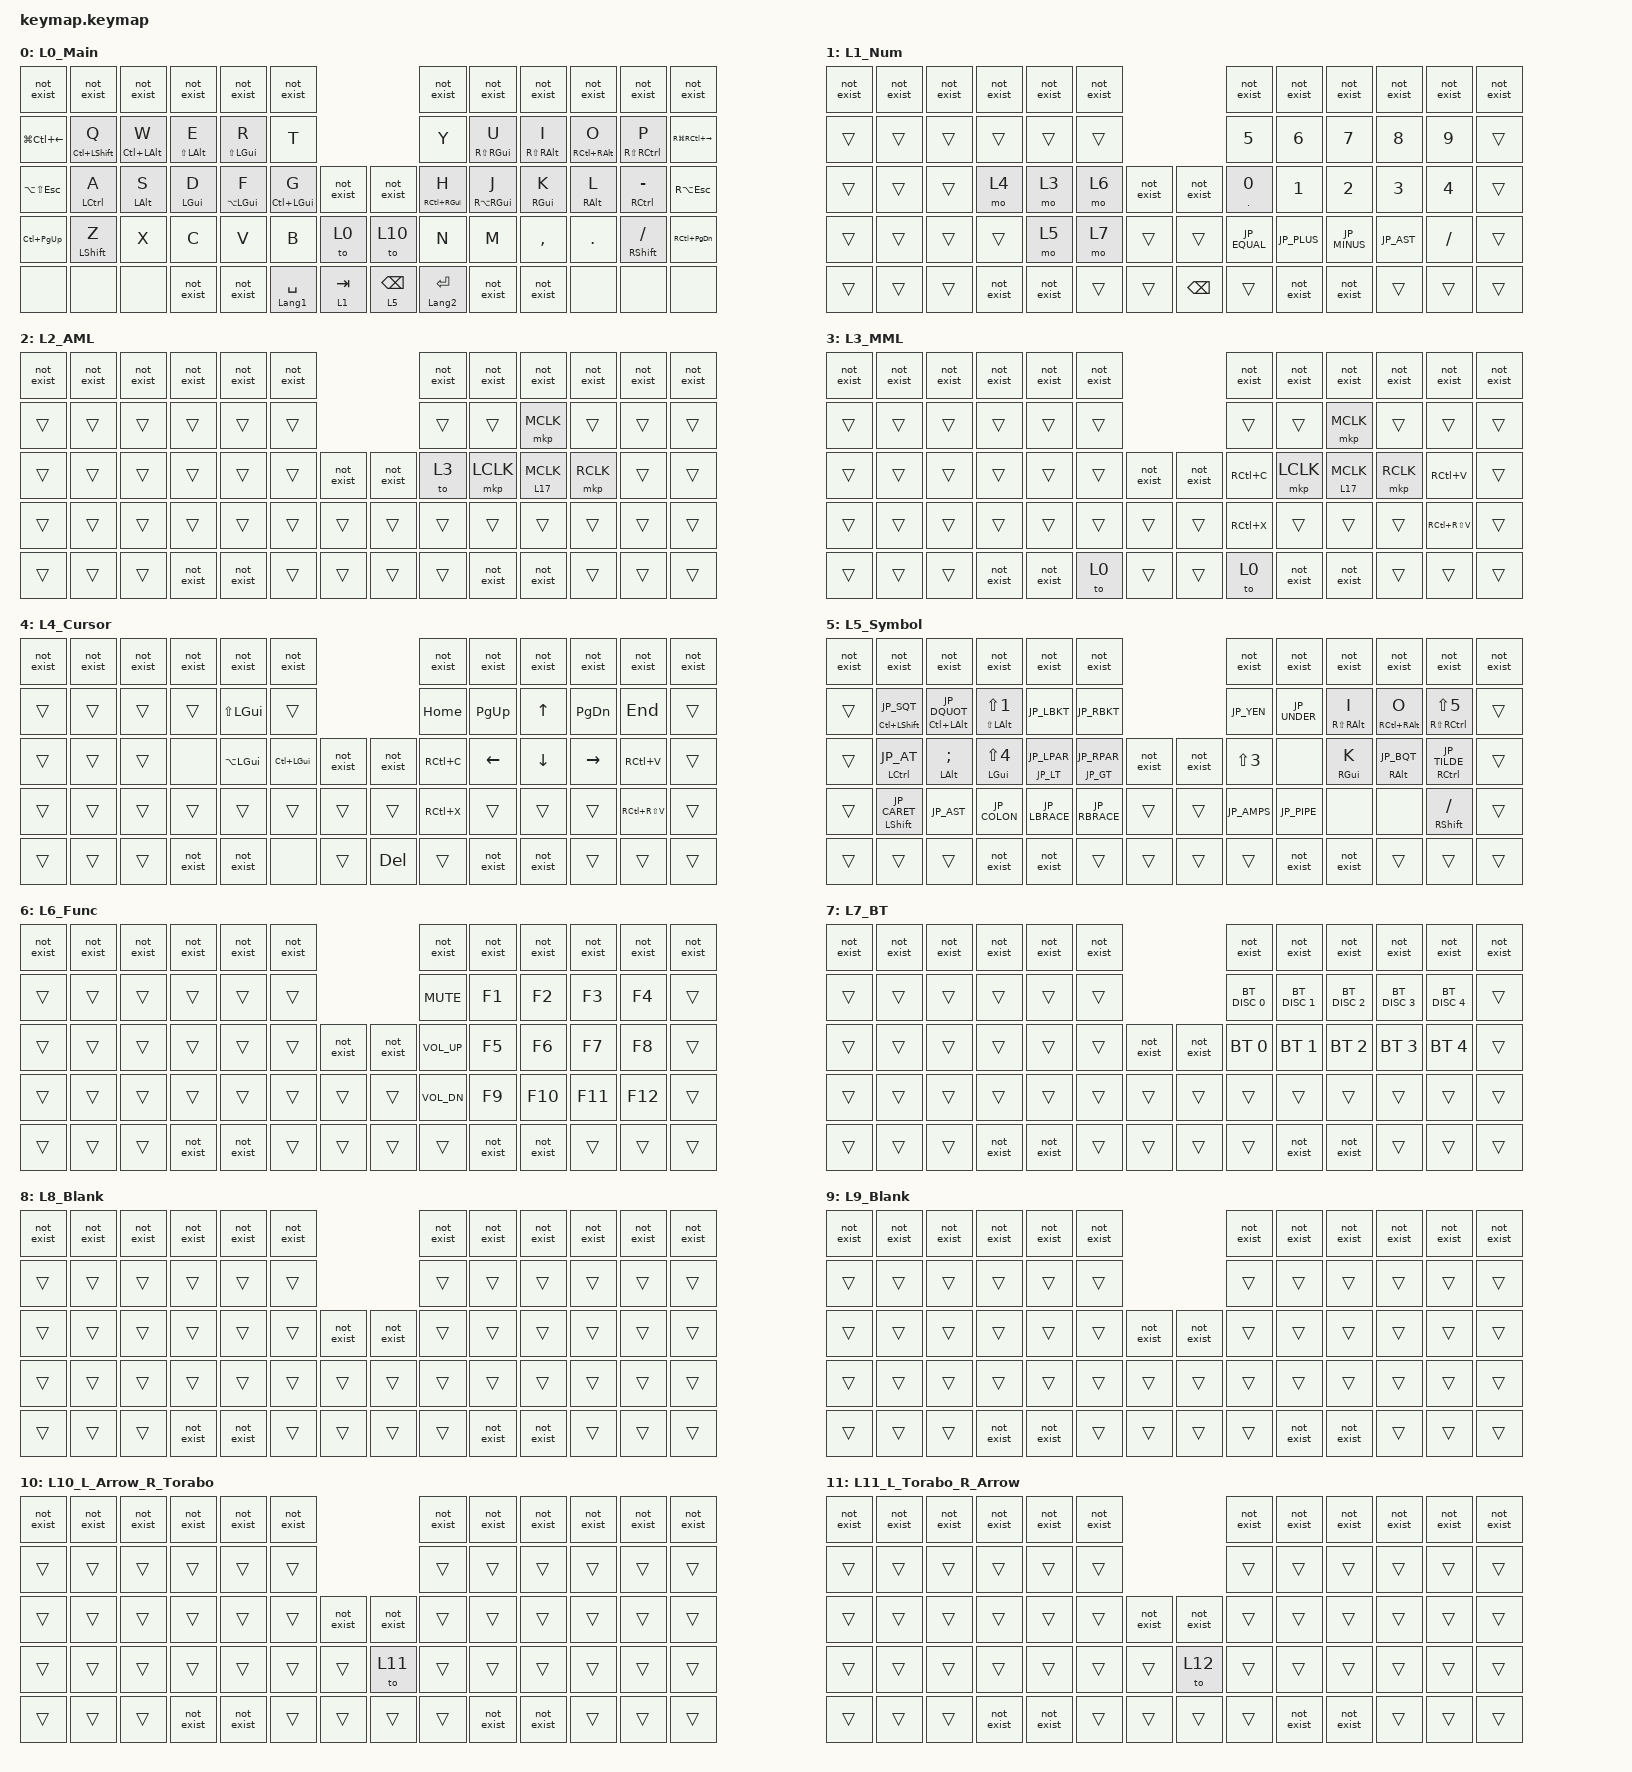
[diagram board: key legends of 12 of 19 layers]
/*
 * ZMK Keymap Configuration
 * 
 * Keyboard: torabo-tsuki lp(M) dual-torabo構成
 * Author: やきそば
 * 
 * 特徴:
 * - 基本はQWERTY配列、A-Ctrl、Z-Shift、S-Alt、D-Winなど
 * - 右小指(Lの右隣)は文章入力でよく使う長音記号（ー）を配置
 * - 左親指で数字レイヤー、+ホームポジション周辺キーで他レイヤーへのハブとしている
 * - 10～12レイヤーで左右トラボの挙動をトグル切り替え
 * - 17～18をスクロールレイヤー（慣性スクロール）
 */

#include <input/processors.dtsi>
#include <zephyr/dt-bindings/input/input-event-codes.h>
#include "keys_ja.h"
#include <dt-bindings/zmk/modifiers.h>
#include <behaviors.dtsi>
#include <dt-bindings/zmk/bt.h>
#include <dt-bindings/zmk/keys.h>
#include <dt-bindings/zmk/pointing.h>

/* --------------------------------------------------------------------------
 * 全般設定 (Global Settings)
 * -------------------------------------------------------------------------- */
// オーバーライド

&mt {
    tapping-term-ms = <150>; // 長押しの判定時間
    quick-tap-ms = <250>;    // 素早く2回叩いた時に連続入力として扱う設定
};

&lt {
    tapping-term-ms = <150>; // 長押しの判定時間
    quick-tap-ms = <250>;    // 素早く2回叩いた時に連続入力として扱う設定
};

/ {
    /* --------------------------------------------------------------------------
     * コンボ設定 (Combos)
     * 特定のキーを同時押しした際のアクション
     * -------------------------------------------------------------------------- */

    combos {
        compatible = "zmk,combos";

        // 13, 14キー(qw)同時押しで ESC

        Esc {
            bindings = <&kp ESC>;
            key-positions = <13 14>;
            slow-release;
        };

        // レイヤー7(BT)にて 47, 48, 49, 50キー(jkl-)同時押しで Bluetooth情報初期化

        BTclr {
            bindings = <&bt BT_CLR>;
            key-positions = <47 48 49 50>;
            slow-release;
            layers = <7>;
            timeout-ms = <0>;
        };

        // 35, 34キー(kl)で横スクロールレイヤー(18)へ

        x_scroll {
            bindings = <&mo 18>;
            key-positions = <35 34>;
            require-prior-idle-ms = <50>;
        };

        // 58, 59きーで BackSpace（連続入力用。でもダブルタップでできるので必要ないかも）

        CapsLock {
            bindings = <&kp LS(CLCK)>;
            key-positions = <39 50>;
        };

        ExitMML {
            bindings = <&to 0>;
            key-positions = <33 34 35>;
            layers = <3>;
        };
    };

    /* --------------------------------------------------------------------------
     * マクロ設定 (Macros)
     * -------------------------------------------------------------------------- */

    macros {
        // レイヤー2 (AML: Auto Mouse Layer) を強制OFFにする

        exit_AML: exit_AML {
            compatible = "zmk,behavior-macro";
            wait-ms = <0>;
            tap-ms = <0>;
            #binding-cells = <0>;
            bindings = <&tog_off 2>;
            label = "exit_AML";
        };

        // パラメータ付きマクロ: キーを入力した後に exit_AML を実行する

        kp_exit_AML: kp_exit_AML {
            compatible = "zmk,behavior-macro-one-param";
            wait-ms = <0>;
            tap-ms = <0>;
            #binding-cells = <1>;
            bindings = <&macro_param_1to1 &kp MACRO_PLACEHOLDER &exit_AML>;
            label = "KP_exit_AML";
        };

        // zip_temp_layer の状態を強制的に折り取るマクロ

        exit_mouse_layer: exit_mouse_layer {
            compatible = "zmk,behavior-macro";
            #binding-cells = <0>;
            wait-ms = <0>;
            tap-ms = <0>;
            bindings = <&tog 2>;
        };
    };

    /* --------------------------------------------------------------------------
     * カスタム挙動 (Behaviors)
     * -------------------------------------------------------------------------- */

    behaviors {
        // 物理的に存在しないキー用の透過設定

        not_exist: not_exist {
            compatible = "zmk,behavior-transparent";
            #binding-cells = <0>;
        };

        // Home Row Mods: 長押しで修飾キー、タップで通常文字

        hm: homerow_mods {
            compatible = "zmk,behavior-hold-tap";
            #binding-cells = <2>;
            tapping-term-ms = <300>;    // ① 時間：200msくらいが標準
            quick-tap-ms = <175>;       // ② 連打時の判定（任意）
            flavor = "tap-preferred";   // ★③ ここが最重要！
            bindings = <&kp>, <&kp>;
        };

        // Home Row Mods (高速入力用・短めの判定)

        hm_s: hm_s {
            compatible = "zmk,behavior-hold-tap";
            #binding-cells = <2>;
            tapping-term-ms = <180>;
            quick-tap-ms = <150>;
            flavor = "tap-preferred";
            bindings = <&kp>, <&kp>;
        };

        // 特定レイヤーをOFFにするトグル挙動

        tog_off: toggle_layer_off {
            compatible = "zmk,behavior-toggle-layer";
            #binding-cells = <1>;
            display-name = "Toggle Layer Off";
            toggle-mode = "off";
        };

        // タップ時にAML(マウス層)を解除しつつキー入力する特殊なHold-Tap

        mt_exit_AML_on_tap: mt_exit_AML_on_tap {
            compatible = "zmk,behavior-hold-tap";
            bindings = <&kp>, <&kp_exit_AML>;

            #binding-cells = <2>;
            tapping-term-ms = <299>;
            quick-tap-ms = <175>;       // ② 連打時の判定（任意）
            flavor = "tap-preferred";   // ★③ ここが最重要！
        };

        // マウスボタン用レイヤーホールド (長押しでレイヤー、タップでクリック)

        ml: ml {
            compatible = "zmk,behavior-hold-tap";
            bindings = <&mo>, <&mkp>;

            #binding-cells = <2>;
            tapping-term-ms = <200>;
        };

        // オートマウス脱出用の「超即時Hold」Behavior
    };

    /* --------------------------------------------------------------------------
     * キーマップ (Keymaps)
     * -------------------------------------------------------------------------- */

    keymap {
        compatible = "zmk,keymap";

        // [0] メインレイヤー: QWERTY配列
        // A-Ctrl、Z-Shift、S‐Alt、D-Win（右手も対称に配置）
        // 親指にはスペース(レイヤー)、タブ(日本語)、BackSpace(英数)、エンター(レイヤー)

        L0_Main {
            bindings = <
&not_exist              &not_exist                        &not_exist          &not_exist          &not_exist          &not_exist                                    &not_exist            &not_exist           &not_exist           &not_exist           &not_exist                            &not_exist
&kp LG(LC(LEFT_ARROW))  &hm LC(LEFT_SHIFT) Q              &hm LC(LEFT_ALT) W  &hm LS(LEFT_ALT) E  &hm LS(LEFT_GUI) R  &kp T                                         &kp Y                 &hm RS(RIGHT_GUI) U  &hm RS(RIGHT_ALT) I  &hm RC(RIGHT_ALT) O  &hm RS(RIGHT_CONTROL) P               &kp RG(RC(RIGHT_ARROW))
&kp LA(LS(ESC))         &mt_exit_AML_on_tap LCTRL A       &hm LEFT_ALT S      &hm LEFT_GUI D      &hm LA(LEFT_GUI) F  &hm LC(LEFT_GUI) G    &not_exist  &not_exist  &hm RC(RIGHT_GUI) H   &hm RA(RIGHT_GUI) J  &hm RIGHT_GUI K      &hm RIGHT_ALT L      &mt_exit_AML_on_tap RCTRL MINUS       &kp RA(ESC)
&kp LC(PAGE_UP)         &mt_exit_AML_on_tap LEFT_SHIFT Z  &kp X               &kp C               &kp V               &kp B                 &to 0       &to 10      &kp N                 &kp M                &kp COMMA            &kp DOT              &mt_exit_AML_on_tap RIGHT_SHIFT FSLH  &kp RC(PAGE_DOWN)
&none                   &none                             &none               &not_exist          &not_exist          &mt LANGUAGE_1 SPACE  &lt 1 TAB   &lt 5 BSPC  &mt LANGUAGE_2 ENTER  &not_exist           &not_exist           &none                &none                                 &none
            >;
        };

        // [1] 数字レイヤー (右手に0-9を二段配置)
        // 左手は親指+ホームポジション周辺の組み合わせで他レイヤーへのハブとしている。

        L1_Num {
            bindings = <
&not_exist  &not_exist  &not_exist  &not_exist  &not_exist  &not_exist                          &not_exist       &not_exist   &not_exist    &not_exist  &not_exist  &not_exist
&trans      &trans      &trans      &trans      &trans      &trans                              &kp N5           &kp N6       &kp N7        &kp N8      &kp N9      &trans
&trans      &trans      &trans      &mo 4       &mo 3       &mo 6       &not_exist  &not_exist  &hm_s PERIOD N0  &kp N1       &kp N2        &kp N3      &kp N4      &trans
&trans      &trans      &trans      &trans      &mo 5       &mo 7       &trans      &trans      &kp JP_EQUAL     &kp JP_PLUS  &kp JP_MINUS  &kp JP_AST  &kp SLASH   &trans
&trans      &trans      &trans      &not_exist  &not_exist  &trans      &trans      &kp BSPC    &trans           &not_exist   &not_exist    &trans      &trans      &trans
            >;
        };

        // [2] AML (Auto Mouse Layer): マウス操作用

        L2_AML {
            bindings = <
&not_exist  &not_exist  &not_exist  &not_exist  &not_exist  &not_exist                          &not_exist  &not_exist  &not_exist   &not_exist  &not_exist  &not_exist
&trans      &trans      &trans      &trans      &trans      &trans                              &trans      &trans      &mkp MCLK    &trans      &trans      &trans
&trans      &trans      &trans      &trans      &trans      &trans      &not_exist  &not_exist  &to 3       &mkp LCLK   &ml 17 MCLK  &mkp RCLK   &trans      &trans
&trans      &trans      &trans      &trans      &trans      &trans      &trans      &trans      &trans      &trans      &trans       &trans      &trans      &trans
&trans      &trans      &trans      &not_exist  &not_exist  &trans      &trans      &trans      &trans      &not_exist  &not_exist   &trans      &trans      &trans
            >;
        };

        // [3] MML (Mouse & Macro Layer): コピー、ペースト等

        L3_MML {
            bindings = <
&not_exist  &not_exist  &not_exist  &not_exist  &not_exist  &not_exist                          &not_exist  &not_exist  &not_exist   &not_exist  &not_exist     &not_exist
&trans      &trans      &trans      &trans      &trans      &trans                              &trans      &trans      &mkp MCLK    &trans      &trans         &trans
&trans      &trans      &trans      &trans      &trans      &trans      &not_exist  &not_exist  &kp RC(C)   &mkp LCLK   &ml 17 MCLK  &mkp RCLK   &kp RC(V)      &trans
&trans      &trans      &trans      &trans      &trans      &trans      &trans      &trans      &kp RC(X)   &trans      &trans       &trans      &kp RC(RS(V))  &trans
&trans      &trans      &trans      &not_exist  &not_exist  &to 0       &trans      &trans      &to 0       &not_exist  &not_exist   &trans      &trans         &trans
            >;
        };

        // [4] カーソルレイヤー: 矢印キー、Home/End等

        L4_Cursor {
            bindings = <
&not_exist  &not_exist  &not_exist  &not_exist  &not_exist        &not_exist                                &not_exist  &not_exist      &not_exist      &not_exist       &not_exist     &not_exist
&trans      &trans      &trans      &trans      &kp LS(LEFT_GUI)  &trans                                    &kp HOME    &kp PAGE_UP     &kp UP_ARROW    &kp PAGE_DOWN    &kp END        &trans
&trans      &trans      &trans      &none       &kp LA(LEFT_GUI)  &kp LC(LEFT_GUI)  &not_exist  &not_exist  &kp RC(C)   &kp LEFT_ARROW  &kp DOWN_ARROW  &kp RIGHT_ARROW  &kp RC(V)      &trans
&trans      &trans      &trans      &trans      &trans            &trans            &trans      &trans      &kp RC(X)   &trans          &trans          &trans           &kp RC(RS(V))  &trans
&trans      &trans      &trans      &not_exist  &not_exist        &none             &trans      &kp DEL     &trans      &not_exist      &not_exist      &trans           &trans         &trans
            >;
        };

        // [5] 記号レイヤー: 下記の記事を参考に、連想しやすい記号配列を設定
        // https://qiita.com/rall_alice/items/1c5cafc15dc8a7ad6236

        L5_Symbol {
            bindings = <
&not_exist  &not_exist                               &not_exist                 &not_exist                     &not_exist           &not_exist                                   &not_exist        &not_exist    &not_exist           &not_exist            &not_exist                             &not_exist
&trans      &hm LC(LEFT_SHIFT) JP_SQT                &hm LC(LEFT_ALT) JP_DQUOT  &hm LS(LEFT_ALT) LS(NUMBER_1)  &kp JP_LBKT          &kp JP_RBKT                                  &kp JP_YEN        &kp JP_UNDER  &hm RS(RIGHT_ALT) I  &hm RC(RIGHT_ALT) O   &hm RS(RIGHT_CONTROL) LS(NUMBER_5)     &trans
&trans      &mt_exit_AML_on_tap LCTRL JP_AT          &hm LEFT_ALT SEMICOLON     &hm LEFT_GUI LS(NUMBER_4)      &hm_s JP_LT JP_LPAR  &hm_s JP_GT JP_RPAR  &not_exist  &not_exist  &kp LS(NUMBER_3)  &none         &hm RIGHT_GUI K      &hm RIGHT_ALT JP_BQT  &mt_exit_AML_on_tap RCTRL JP_TILDE     &trans
&trans      &mt_exit_AML_on_tap LEFT_SHIFT JP_CARET  &kp JP_AST                 &kp JP_COLON                   &kp JP_LBRACE        &kp JP_RBRACE        &trans      &trans      &kp JP_AMPS       &kp JP_PIPE   &none                &none                 &mt_exit_AML_on_tap RIGHT_SHIFT SLASH  &trans
&trans      &trans                                   &trans                     &not_exist                     &not_exist           &trans               &trans      &trans      &trans            &not_exist    &not_exist           &trans                &trans                                 &trans
            >;
        };

        // [6] ファンクションレイヤー: F1-F12（おまけで音量調節）

        L6_Func {
            bindings = <
&not_exist  &not_exist  &not_exist  &not_exist  &not_exist  &not_exist                          &not_exist    &not_exist  &not_exist  &not_exist  &not_exist  &not_exist
&trans      &trans      &trans      &trans      &trans      &trans                              &kp C_MUTE    &kp F1      &kp F2      &kp F3      &kp F4      &trans
&trans      &trans      &trans      &trans      &trans      &trans      &not_exist  &not_exist  &kp C_VOL_UP  &kp F5      &kp F6      &kp F7      &kp F8      &trans
&trans      &trans      &trans      &trans      &trans      &trans      &trans      &trans      &kp C_VOL_DN  &kp F9      &kp F10     &kp F11     &kp F12     &trans
&trans      &trans      &trans      &not_exist  &not_exist  &trans      &trans      &trans      &trans        &not_exist  &not_exist  &trans      &trans      &trans
            >;
        };

        // [7] Bluetoothレイヤー: 接続先の切り替え・解除

        L7_BT {
            bindings = <
&not_exist  &not_exist  &not_exist  &not_exist  &not_exist  &not_exist                          &not_exist     &not_exist     &not_exist     &not_exist     &not_exist     &not_exist
&trans      &trans      &trans      &trans      &trans      &trans                              &bt BT_DISC 0  &bt BT_DISC 1  &bt BT_DISC 2  &bt BT_DISC 3  &bt BT_DISC 4  &trans
&trans      &trans      &trans      &trans      &trans      &trans      &not_exist  &not_exist  &bt BT_SEL 0   &bt BT_SEL 1   &bt BT_SEL 2   &bt BT_SEL 3   &bt BT_SEL 4   &trans
&trans      &trans      &trans      &trans      &trans      &trans      &trans      &trans      &trans         &trans         &trans         &trans         &trans         &trans
&trans      &trans      &trans      &not_exist  &not_exist  &trans      &trans      &trans      &trans         &not_exist     &not_exist     &trans         &trans         &trans
            >;
        };

        // [8] 空レイヤー (予約)

        L8_Blank {
            bindings = <
&not_exist  &not_exist  &not_exist  &not_exist  &not_exist  &not_exist                          &not_exist  &not_exist  &not_exist  &not_exist  &not_exist  &not_exist
&trans      &trans      &trans      &trans      &trans      &trans                              &trans      &trans      &trans      &trans      &trans      &trans
&trans      &trans      &trans      &trans      &trans      &trans      &not_exist  &not_exist  &trans      &trans      &trans      &trans      &trans      &trans
&trans      &trans      &trans      &trans      &trans      &trans      &trans      &trans      &trans      &trans      &trans      &trans      &trans      &trans
&trans      &trans      &trans      &not_exist  &not_exist  &trans      &trans      &trans      &trans      &not_exist  &not_exist  &trans      &trans      &trans
            >;
        };

        // [9] 空レイヤー (予約)

        L9_Blank {
            bindings = <
&not_exist  &not_exist  &not_exist  &not_exist  &not_exist  &not_exist                          &not_exist  &not_exist  &not_exist  &not_exist  &not_exist  &not_exist
&trans      &trans      &trans      &trans      &trans      &trans                              &trans      &trans      &trans      &trans      &trans      &trans
&trans      &trans      &trans      &trans      &trans      &trans      &not_exist  &not_exist  &trans      &trans      &trans      &trans      &trans      &trans
&trans      &trans      &trans      &trans      &trans      &trans      &trans      &trans      &trans      &trans      &trans      &trans      &trans      &trans
&trans      &trans      &trans      &not_exist  &not_exist  &trans      &trans      &trans      &trans      &not_exist  &not_exist  &trans      &trans      &trans
            >;
        };

        // [10] 左右トラボ挙動レイヤーをトグル切り替え（0→10→11→12→0）
        // 左トラボ：矢印キー入力、右トラボ：通常

        L10_L_Arrow_R_Torabo {
            bindings = <
&not_exist  &not_exist  &not_exist  &not_exist  &not_exist  &not_exist                          &not_exist  &not_exist  &not_exist  &not_exist  &not_exist  &not_exist
&trans      &trans      &trans      &trans      &trans      &trans                              &trans      &trans      &trans      &trans      &trans      &trans
&trans      &trans      &trans      &trans      &trans      &trans      &not_exist  &not_exist  &trans      &trans      &trans      &trans      &trans      &trans
&trans      &trans      &trans      &trans      &trans      &trans      &trans      &to 11      &trans      &trans      &trans      &trans      &trans      &trans
&trans      &trans      &trans      &not_exist  &not_exist  &trans      &trans      &trans      &trans      &not_exist  &not_exist  &trans      &trans      &trans
            >;
        };

        // [11] 左右トラボ挙動レイヤーをトグル切り替え（0→10→11→12→0）
        // 左トラボ：通常、右トラボ：矢印入力

        L11_L_Torabo_R_Arrow {
            bindings = <
&not_exist  &not_exist  &not_exist  &not_exist  &not_exist  &not_exist                          &not_exist  &not_exist  &not_exist  &not_exist  &not_exist  &not_exist
&trans      &trans      &trans      &trans      &trans      &trans                              &trans      &trans      &trans      &trans      &trans      &trans
&trans      &trans      &trans      &trans      &trans      &trans      &not_exist  &not_exist  &trans      &trans      &trans      &trans      &trans      &trans
&trans      &trans      &trans      &trans      &trans      &trans      &trans      &to 12      &trans      &trans      &trans      &trans      &trans      &trans
&trans      &trans      &trans      &not_exist  &not_exist  &trans      &trans      &trans      &trans      &not_exist  &not_exist  &trans      &trans      &trans
            >;
        };

        // [11] 左右トラボ挙動レイヤーをトグル切り替え（0→10→11→12→0）
        // 左トラボ：通常、右トラボ：矢印入力

        L12_L_Blank_R_Blank {
            bindings = <
&not_exist  &not_exist  &not_exist  &not_exist  &not_exist  &not_exist                          &not_exist  &not_exist  &not_exist  &not_exist  &not_exist  &not_exist
&trans      &trans      &trans      &trans      &trans      &trans                              &trans      &trans      &trans      &trans      &trans      &trans
&trans      &trans      &trans      &trans      &trans      &trans      &not_exist  &not_exist  &trans      &trans      &trans      &trans      &trans      &trans
&trans      &trans      &trans      &trans      &trans      &trans      &trans      &to 0       &trans      &trans      &trans      &trans      &trans      &trans
&trans      &trans      &trans      &not_exist  &not_exist  &trans      &trans      &trans      &trans      &not_exist  &not_exist  &trans      &trans      &trans
            >;
        };

        // [13] 空レイヤー (予約)

        L13_Blank {
            bindings = <
&not_exist  &not_exist  &not_exist  &not_exist  &not_exist  &not_exist                          &not_exist  &not_exist  &not_exist  &not_exist  &not_exist  &not_exist
&trans      &trans      &trans      &trans      &trans      &trans                              &trans      &trans      &trans      &trans      &trans      &trans
&trans      &trans      &trans      &trans      &trans      &trans      &not_exist  &not_exist  &trans      &trans      &trans      &trans      &trans      &trans
&trans      &trans      &trans      &trans      &trans      &trans      &trans      &trans      &trans      &trans      &trans      &trans      &trans      &trans
&trans      &trans      &trans      &not_exist  &not_exist  &trans      &trans      &trans      &trans      &not_exist  &not_exist  &trans      &trans      &trans
            >;
        };

        // [14] 空レイヤー (予約)

        L14_Blank {
            bindings = <
&not_exist  &not_exist  &not_exist  &not_exist  &not_exist  &not_exist                          &not_exist  &not_exist  &not_exist  &not_exist  &not_exist  &not_exist
&trans      &trans      &trans      &trans      &trans      &trans                              &trans      &trans      &trans      &trans      &trans      &trans
&trans      &trans      &trans      &trans      &trans      &trans      &not_exist  &not_exist  &trans      &trans      &trans      &trans      &trans      &trans
&trans      &trans      &trans      &trans      &trans      &trans      &trans      &trans      &trans      &trans      &trans      &trans      &trans      &trans
&trans      &trans      &trans      &not_exist  &not_exist  &trans      &trans      &trans      &trans      &not_exist  &not_exist  &trans      &trans      &trans
            >;
        };

        // [15] 空レイヤー (予約)

        L15_Blank {
            bindings = <
&not_exist  &not_exist  &not_exist  &not_exist  &not_exist  &not_exist                          &not_exist  &not_exist  &not_exist  &not_exist  &not_exist  &not_exist
&trans      &trans      &trans      &trans      &trans      &trans                              &trans      &trans      &trans      &trans      &trans      &trans
&trans      &trans      &trans      &trans      &trans      &trans      &not_exist  &not_exist  &trans      &trans      &trans      &trans      &trans      &trans
&trans      &trans      &trans      &trans      &trans      &trans      &trans      &trans      &trans      &trans      &trans      &trans      &trans      &trans
&trans      &trans      &trans      &not_exist  &not_exist  &trans      &trans      &trans      &trans      &not_exist  &not_exist  &trans      &trans      &trans
            >;
        };

        // [16] 空レイヤー (予約)

        L16_Blank {
            bindings = <
&not_exist  &not_exist  &not_exist  &not_exist  &not_exist  &not_exist                          &not_exist  &not_exist  &not_exist  &not_exist  &not_exist  &not_exist
&trans      &trans      &trans      &trans      &trans      &trans                              &trans      &trans      &trans      &trans      &trans      &trans
&trans      &trans      &trans      &trans      &trans      &trans      &not_exist  &not_exist  &trans      &trans      &trans      &trans      &trans      &trans
&trans      &trans      &trans      &trans      &trans      &trans      &trans      &trans      &trans      &trans      &trans      &trans      &trans      &trans
&trans      &trans      &trans      &not_exist  &not_exist  &trans      &trans      &trans      &trans      &not_exist  &not_exist  &trans      &trans      &trans
            >;
        };

        // [17] Yscroll (右垂直スクロール)
        // 左トラボはXスクロール

        L17_L_Xscroll_R_Yscroll {
            bindings = <
&not_exist  &not_exist  &not_exist  &not_exist  &not_exist  &not_exist                          &not_exist  &not_exist  &not_exist  &not_exist  &not_exist  &not_exist
&trans      &trans      &trans      &trans      &trans      &trans                              &trans      &trans      &trans      &trans      &trans      &trans
&trans      &trans      &trans      &trans      &trans      &trans      &not_exist  &not_exist  &trans      &trans      &trans      &trans      &trans      &trans
&trans      &trans      &trans      &trans      &trans      &trans      &trans      &trans      &trans      &trans      &trans      &trans      &trans      &trans
&trans      &trans      &trans      &not_exist  &not_exist  &trans      &trans      &trans      &trans      &not_exist  &not_exist  &trans      &trans      &trans
            >;
        };

        // [18] Xscroll (右水平スクロール)
        // 左トラボはYスクロール

        L18_L_Yscroll_R_Xscroll {
            bindings = <
&not_exist  &not_exist  &not_exist  &not_exist  &not_exist  &not_exist                          &not_exist  &not_exist  &not_exist  &not_exist  &not_exist  &not_exist
&trans      &trans      &trans      &trans      &trans      &trans                              &trans      &trans      &trans      &trans      &trans      &trans
&trans      &trans      &trans      &trans      &trans      &trans      &not_exist  &not_exist  &trans      &trans      &trans      &trans      &trans      &trans
&trans      &trans      &trans      &trans      &trans      &trans      &trans      &trans      &trans      &trans      &trans      &trans      &trans      &trans
&trans      &trans      &trans      &not_exist  &not_exist  &trans      &trans      &trans      &trans      &not_exist  &not_exist  &trans      &trans      &trans
            >;
        };
    };
};
